BO_ 228 STEERING_CONTROL: 5 ADAS
 SG_ STEER_TORQUE : 7|16@0- (1,0) [-3840|3840] "" EPS
 SG_ STEER_TORQUE_REQUEST : 23|1@0+ (1,0) [0|1] "" EPS
 SG_ SET_ME_X00 : 22|7@0+ (1,0) [0|127] "" EPS
 SG_ SET_ME_X00_2 : 31|8@0+ (1,0) [0|0] "" EPS
 SG_ COUNTER : 37|2@0+ (1,0) [0|3] "" EPS
 SG_ CHECKSUM : 35|4@0+ (1,0) [0|15] "" EPS
 SG_ TORQUE_BLEND_DISABLE : 16|1@0+ (1,0) [0|1] "" EPS
 SG_ TX_ALL_LKAS_DATA : 17|1@0+ (1,0) [0|1] "" EPS
 SG_ LSB_TOGGLE_DISABLE : 18|1@0+ (1,0) [0|1] "" EPS
 SG_ ZERO_TORQUE_KEEPS_LKAS_ON : 19|1@0+ (1,0) [0|1] "" EPS

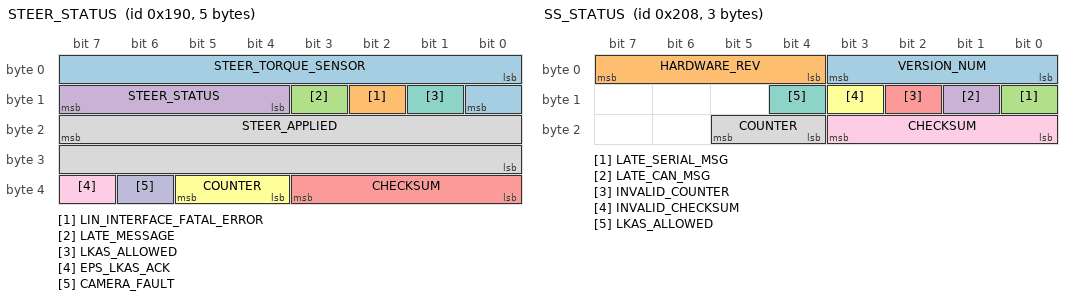
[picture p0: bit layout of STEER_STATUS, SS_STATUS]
BO_ 400 STEER_STATUS: 5 EPS
 SG_ STEER_TORQUE_SENSOR : 0|9@1- (1,0) [-256|256] "" XXX
 SG_ LIN_INTERFACE_FATAL_ERROR : 10|1@0+ (1,0) [0|1] "" XXX
 SG_ LATE_MESSAGE : 11|1@0+ (1,0) [0|1] "" XXX
 SG_ STEER_STATUS : 12|4@1+ (1,0) [0|15] "" XXX
 SG_ CHECKSUM : 35|4@0+ (1,0) [0|3] "" EON
 SG_ COUNTER : 37|2@0+ (1,0) [0|3] "" XXX
 SG_ LKAS_ALLOWED : 9|1@0+ (1,0) [0|1] "" XXX
 SG_ STEER_APPLIED : 23|16@0- (1,0) [0|511] "" XXX
 SG_ EPS_LKAS_ACK : 39|1@0+ (1,0) [0|1] "" XXX
 SG_ CAMERA_FAULT : 38|1@0+ (1,0) [0|1] "" XXX

BO_ 520 SS_STATUS: 3 EPS
 SG_ VERSION_NUM : 0|4@1+ (1,0) [0|15] "" XXX
 SG_ HARDWARE_REV : 7|4@0+ (1,0) [0|15] "" XXX
 SG_ LATE_SERIAL_MSG : 8|1@0+ (1,0) [0|1] "" XXX
 SG_ LATE_CAN_MSG : 9|1@0+ (1,0) [0|1] "" XXX
 SG_ INVALID_COUNTER : 10|1@0+ (1,0) [0|1] "" XXX
 SG_ INVALID_CHECKSUM : 11|1@0+ (1,0) [0|1] "" XXX
 SG_ LKAS_ALLOWED : 12|1@0+ (1,0) [0|1] "" XXX
 SG_ COUNTER : 21|2@0+ (1,0) [0|3] "" XXX
 SG_ CHECKSUM : 19|4@0+ (1,0) [0|15] "" XXX

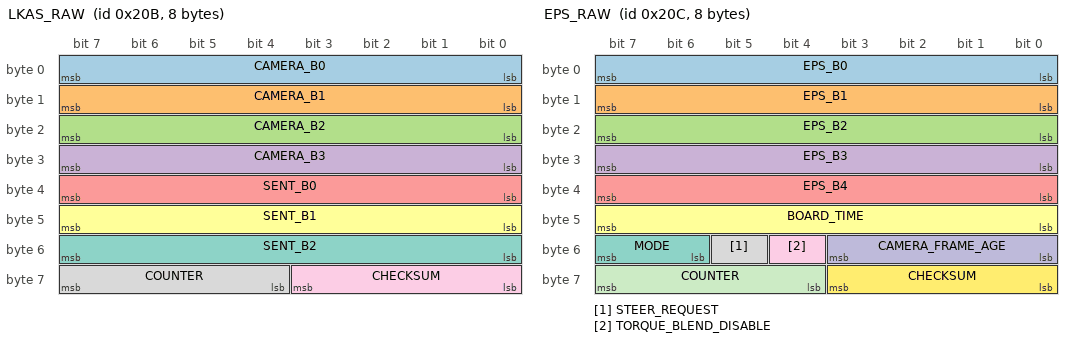
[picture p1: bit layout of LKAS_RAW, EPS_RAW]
BO_ 523 LKAS_RAW: 8 EPS
 SG_ CAMERA_B0 : 7|8@0+ (1,0) [0|255] "" XXX
 SG_ CAMERA_B1 : 15|8@0+ (1,0) [0|255] "" XXX
 SG_ CAMERA_B2 : 23|8@0+ (1,0) [0|255] "" XXX
 SG_ CAMERA_B3 : 31|8@0+ (1,0) [0|255] "" XXX
 SG_ SENT_B0 : 39|8@0+ (1,0) [0|255] "" XXX
 SG_ SENT_B1 : 47|8@0+ (1,0) [0|255] "" XXX
 SG_ SENT_B2 : 55|8@0+ (1,0) [0|255] "" XXX
 SG_ COUNTER : 63|4@0+ (1,0) [0|15] "" XXX
 SG_ CHECKSUM : 59|4@0+ (1,0) [0|15] "" XXX

BO_ 524 EPS_RAW: 8 EPS
 SG_ EPS_B0 : 7|8@0+ (1,0) [0|255] "" XXX
 SG_ EPS_B1 : 15|8@0+ (1,0) [0|255] "" XXX
 SG_ EPS_B2 : 23|8@0+ (1,0) [0|255] "" XXX
 SG_ EPS_B3 : 31|8@0+ (1,0) [0|255] "" XXX
 SG_ EPS_B4 : 39|8@0+ (1,0) [0|255] "" XXX
 SG_ BOARD_TIME : 47|8@0+ (1,0) [0|255] "ms" XXX
 SG_ MODE : 55|2@0+ (1,0) [0|2] "" XXX
 SG_ STEER_REQUEST : 53|1@0+ (1,0) [0|1] "" XXX
 SG_ TORQUE_BLEND_DISABLE : 52|1@0+ (1,0) [0|1] "" XXX
 SG_ CAMERA_FRAME_AGE : 51|4@0+ (1,0) [0|15] "ms" XXX
 SG_ COUNTER : 63|4@0+ (1,0) [0|15] "" XXX
 SG_ CHECKSUM : 59|4@0+ (1,0) [0|15] "" XXX

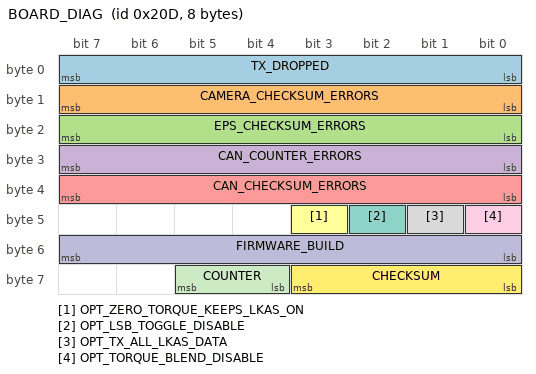
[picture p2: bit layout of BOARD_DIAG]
BO_ 525 BOARD_DIAG: 8 EPS
 SG_ TX_DROPPED : 7|8@0+ (1,0) [0|255] "" XXX
 SG_ CAMERA_CHECKSUM_ERRORS : 15|8@0+ (1,0) [0|255] "" XXX
 SG_ EPS_CHECKSUM_ERRORS : 23|8@0+ (1,0) [0|255] "" XXX
 SG_ CAN_COUNTER_ERRORS : 31|8@0+ (1,0) [0|255] "" XXX
 SG_ CAN_CHECKSUM_ERRORS : 39|8@0+ (1,0) [0|255] "" XXX
 SG_ OPT_ZERO_TORQUE_KEEPS_LKAS_ON : 43|1@0+ (1,0) [0|1] "" XXX
 SG_ OPT_LSB_TOGGLE_DISABLE : 42|1@0+ (1,0) [0|1] "" XXX
 SG_ OPT_TX_ALL_LKAS_DATA : 41|1@0+ (1,0) [0|1] "" XXX
 SG_ OPT_TORQUE_BLEND_DISABLE : 40|1@0+ (1,0) [0|1] "" XXX
 SG_ FIRMWARE_BUILD : 55|8@0+ (1,0) [0|255] "" XXX
 SG_ COUNTER : 61|2@0+ (1,0) [0|3] "" XXX
 SG_ CHECKSUM : 59|4@0+ (1,0) [0|15] "" XXX

CM_ "SSV3 serial-steering board on the 2016-17 Accord (9G). Frames 228 and 400 are _steering_control_d_ext.dbc verbatim plus new signals (test_ssv3_dbc.py checks that); 520/523/524/525 are the board's own frames. Layout source: LKAS_EPS_V3 dbc/lkas_eps_v3.dbc (firmware 3). Every new signal is zero or absent on firmware 2 or must be gated on SS_STATUS.VERSION_NUM >= 3 (firmware 2 uses 400 bit 39 for its own steer-blended flag).";
CM_ SG_ 228 TORQUE_BLEND_DISABLE "Firmware 3 option: no on-board rate or driver-torque limiting, request only clamped to +-255. Firmware 2 reads this bit as 'disable torque limiting': never set it unless VERSION_NUM >= 3";
CM_ SG_ 228 TX_ALL_LKAS_DATA "Firmware 3 option: request raw frames 523/524 (on by default in firmware 3). Firmware 2 reads this bit as 'send debug frame 521'";
CM_ SG_ 228 LSB_TOGGLE_DISABLE "Firmware 3 option: send bit 0 of the torque as requested instead of alternating it";
CM_ SG_ 228 ZERO_TORQUE_KEEPS_LKAS_ON "Firmware 3 option: a zero-torque request keeps LKAS on instead of sending the LKAS-off frame";
CM_ SG_ 400 EPS_LKAS_ACK "Firmware 3 only (firmware 2: steer-blended flag). EPS reports LKAS engaged; lags the request by about 120 ms";
CM_ SG_ 400 CAMERA_FAULT "Firmware 3 only. Camera serial byte 2 bit 2; meaning believed, not confirmed";
CM_ SG_ 520 LKAS_ALLOWED "Inverted despite its name: 1 = the board cannot steer for openpilot";
CM_ SG_ 523 SENT_B0 "First three bytes of the frame given to the EPS; the fourth is their serial checksum";
CM_ SG_ 524 BOARD_TIME "Board millisecond clock, low 8 bits, when the EPS frame completed";
CM_ SG_ 524 CAMERA_FRAME_AGE "Milliseconds since the current camera frame began, saturating at 15";
CM_ SG_ 525 FIRMWARE_BUILD "VERSION_BUILD from the board's include/version.h";
CM_ SG_ 525 TX_DROPPED "CAN frames the board could not queue since boot, saturating";
VAL_ 400 STEER_STATUS 7 "permanent_fault" 6 "tmp_fault" 5 "fault_1" 4 "no_torque_alert_2" 3 "low_speed_lockout" 2 "no_torque_alert_1" 1 "driver_steering" 0 "normal" ;
VAL_ 524 MODE 0 "PASSTHROUGH" 1 "IDLE" 2 "STEER" ;
